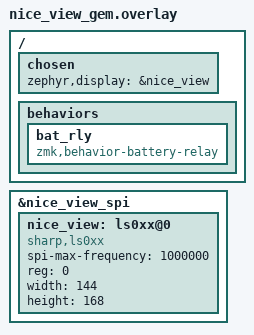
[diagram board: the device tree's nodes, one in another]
/*
 * Copyright (c) 2022 The ZMK Contributors
 *
 * SPDX-License-Identifier: MIT
 */

&nice_view_spi {
    status = "okay";
    nice_view: ls0xx@0 {
        compatible = "sharp,ls0xx";
        spi-max-frequency = <1000000>;
        reg = <0>;
        width = <144>;
        height = <168>;
    };
};

/ {
    chosen {
        zephyr,display = &nice_view;
    };
};

/ {
    behaviors {
        // Node name is the behavior device name the dongle invokes over split;
        // must stay <= 8 chars (ZMK_SPLIT_RUN_BEHAVIOR_DEV_LEN - 1).
        bat_rly: bat_rly {
            compatible = "zmk,behavior-battery-relay";
            #binding-cells = <1>;
        };
    };
};
